# MCU_CPSW0_NUSS_SS register map
Vendor: Texas Instruments
Peripheral module from a debugger description file (folder am65x).
Registers are 32-bit, read-write, reset 0x0 unless marked. A register's access mark holds for its fields unless they carry their own. Offsets are as the file gives them; lines under a group give offsets from that group; [hi:lo] are bit positions; {n}, {i} and the like mark numbered series; 'fields as' and 'values as' point back to an identical list; <NAME> marks a mode.

## MCU_CPSW0_NUSS_SS
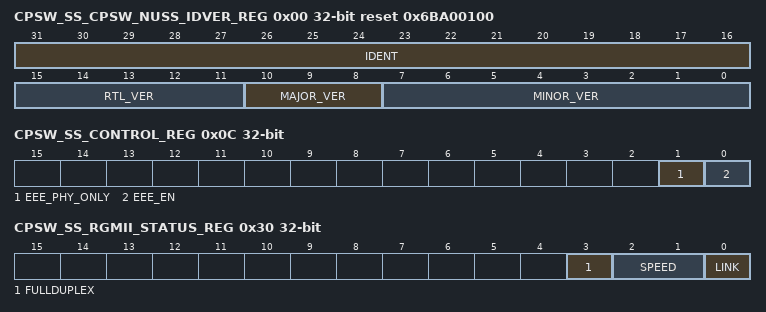
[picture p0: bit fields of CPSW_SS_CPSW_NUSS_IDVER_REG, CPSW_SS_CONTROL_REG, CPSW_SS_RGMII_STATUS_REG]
0x00 CPSW_SS_CPSW_NUSS_IDVER_REG ro reset 0x6BA00100 (reset mask 0xFFFF0700) — ID Version Register
  [31:16] IDENT — Identification Value
  [15:11] RTL_VER — RTL version valueSR2.0: 0hSR1.0: Eh
  [10:8] MAJOR_VER — Major version value
  [7:0] MINOR_VER — Minor Version ValueSR2.0: 2hSR1.0: 0h
0x04 CPSW_SS_SYNCE_COUNT_REG — SyncE Count Register
  [31:0] SYNCE_CNT — Sync E Count Value.
0x08 CPSW_SS_SYNCE_MUX_REG — SGMII_MODE Input. SGMII mode is not supported on the 2-port CPSW module.
  [5:0] SYNCE_SEL — SGMII_MODE Input. Note: SGMII mode is not supported on the 2-port CPSW module.
0x0C CPSW_SS_CONTROL_REG — Subsystem Control Register
  [1] EEE_PHY_ONLY — Energy Efficient Enable Phy Only Mode
  [0] EEE_EN — Energy Efficient Ethernet Enable
0x10 CPSW_SS_SGMII_MODE_REG reset 0x1 — SGMII Mode Register. Note: SGMII mode is not supported on the 2-port CPSW module.
  [0] SYNCE_SEL — SGMII_MODE Input. Note: SGMII mode is not supported on the 2-port CPSW module.
0x1C CPSW_SS_SUBSSYSTEM_STATUS_REG ro — Subsystem Status Register
  [0] EEE_CLKSTOP_ACK — Energy Efficient Ethernet Clockstop Acknowledge.
0x30 CPSW_SS_RGMII_STATUS_REG ro — RGMII Port 1 Register
  [3] FULLDUPLEX — RGMII Fullduplex
  [2:1] SPEED — RGMII_speed
  [0] LINK — RGMII Link Indicator
